# Generic_ARMv6M register map
Vendor: ARM Ltd.; Series: ARMv6-M architecture (Cortex-M0 / Cortex-M0+ / Cortex-M1 / SC000); File version: 1.0
CPU: CM0 r0p0, little endian, no MPU, no FPU, 2 interrupt priority bits
Registers are 32-bit, read-write, reset 0x0 unless marked. A register's access mark holds for its fields unless they carry their own. Offsets are from the block's base; [hi:lo] are bit positions; {n}, {i} and the like mark numbered series.

## NVIC — Nested Vectored Interrupt Controller. ARMv6-M caps external interrupts at 32 (5-bit encoding), so exactly one ISER/ICER/ISPR/ICPR register and 8 IPR registers cover the whole architectural range -- true for every ARMv6-M device regardless of how many interrupt lines it actually implements (unimplemented lines simply read as 0 / writes ignored). No IABR and no STIR on ARMv6-M (both are ARMv7-M+ only).
Base 0xE000E100
0x00 ISER — Interrupt Set-Enable Register
  [31:0] SETENA
0x80 ICER — Interrupt Clear-Enable Register
  [31:0] CLRENA
0x100 ISPR — Interrupt Set-Pending Register
  [31:0] SETPEND
0x180 ICPR — Interrupt Clear-Pending Register
  [31:0] CLRPEND
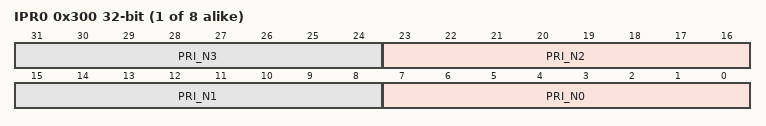
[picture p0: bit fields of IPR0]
{0x300+4i} IPR{i} (i=0..7) — Interrupt Priority Register {i} (covers IRQ{4i}..IRQ{4i+3})
  [8n+7:8n] PRI_N{n} (n=0..3) — Priority, byte offset {n}

## SCB — System Control Block, ARMv6-M register set. Verified against CMSIS_6 core_cm0.h/core_cm0plus.h defines. No SHPR1, no CFSR/HFSR/MMFAR/BFAR/AFSR (no MemManage/BusFault/UsageFault on v6-M), no AIRCR.PRIGROUP/VECTRESET, no ICSR.RETTOBASE (all ARMv7-M+ only). SHCSR exists but with only one bit (SVCALLPENDED) implemented. VTOR is present in the address map but is only wired up on implementations with __VTOR_PRESENT=1 (e.g. Cortex-M0+); on plain Cortex-M0 that offset is reserved. SHCSR and DFSR are only accessible over the DAP (debugger), not from application code -- see the CoreDebug peripheral's description.
Base 0xE000ED00
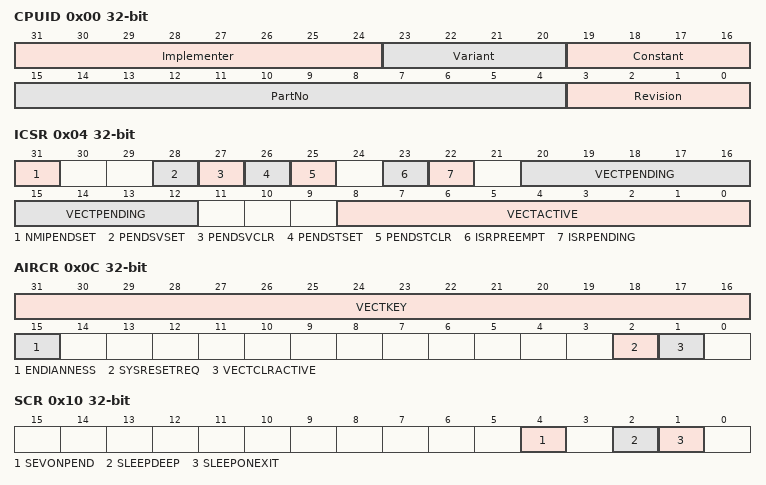
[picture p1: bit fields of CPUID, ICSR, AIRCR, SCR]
0x00 CPUID ro — CPUID Base Register. Reset value is implementation/revision specific.
  [31:24] Implementer — 0x41 = 'A' = ARM
  [23:20] Variant — Implementation specific variant number
  [19:16] Constant — Reads as 0xC for ARMv6-M, 0xF for ARMv7-M/ARMv8-M
  [15:4] PartNo — Implementation specific part number
  [3:0] Revision — Implementation/revision specific (e.g. r0p0 = 0x0)
0x04 ICSR — Interrupt Control and State Register. No RETTOBASE (ARMv7-M+ only).
  [31] NMIPENDSET
  [28] PENDSVSET
  [27] PENDSVCLR wo
  [26] PENDSTSET
  [25] PENDSTCLR wo
  [23] ISRPREEMPT ro — Only meaningful with a debugger attached
  [22] ISRPENDING ro
  [20:12] VECTPENDING — Pending exception number
  [8:0] VECTACTIVE — Active exception number
0x08 VTOR — Vector Table Offset Register -- OPTIONAL: only present if the implementation sets __VTOR_PRESENT=1 (common on Cortex-M0+, absent on plain Cortex-M0). Reads as 0 / reserved otherwise.
  [31:7] TBLOFF — Vector table base offset, 128-byte aligned
0x0C AIRCR — Application Interrupt and Reset Control Register. No PRIGROUP or VECTRESET (both ARMv7-M+ only -- v6-M has no configurable priority grouping).
  [31:16] VECTKEY — Write 0x05FA to permit the write; reads as 0xFA05
  [15] ENDIANNESS ro — Renamed from ENDIANESS in CMSIS_6 (kept as a deprecated alias there)
  [2] SYSRESETREQ
  [1] VECTCLRACTIVE — Reserved for debug use
0x10 SCR — System Control Register
  [4] SEVONPEND, [2] SLEEPDEEP, [1] SLEEPONEXIT
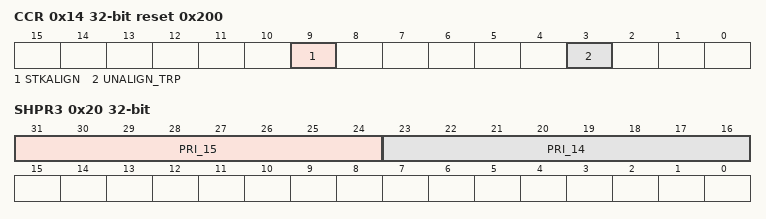
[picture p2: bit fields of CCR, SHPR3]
0x14 CCR reset 0x200 — Configuration and Control Register
  [9] STKALIGN — Always reads as 1: 8-byte stack alignment on exception entry
  [3] UNALIGN_TRP — Trap on unaligned word/halfword access
0x1C SHPR2 — System Handler Priority Register 2
  [31:24] PRI_11 — Priority of exception 11, SVCall
0x20 SHPR3 — System Handler Priority Register 3
  [31:24] PRI_15 — Priority of exception 15, SysTick
  [23:16] PRI_14 — Priority of exception 14, PendSV
0x24 SHCSR — System Handler Control and State Register. DAP-only access on ARMv6-M.
  [15] SVCALLPENDED — The only bit implemented on ARMv6-M

## MPU — Memory Protection Unit -- OPTIONAL on ARMv6-M: never present on plain Cortex-M0, but commonly implemented on Cortex-M0+ and SC000 (__MPU_PRESENT=1). No alias registers on this profile (verified against CMSIS core_cm0plus.h: MPU_TYPE_RALIASES=1, i.e. RBAR/RASR only).
Base 0xE000ED90
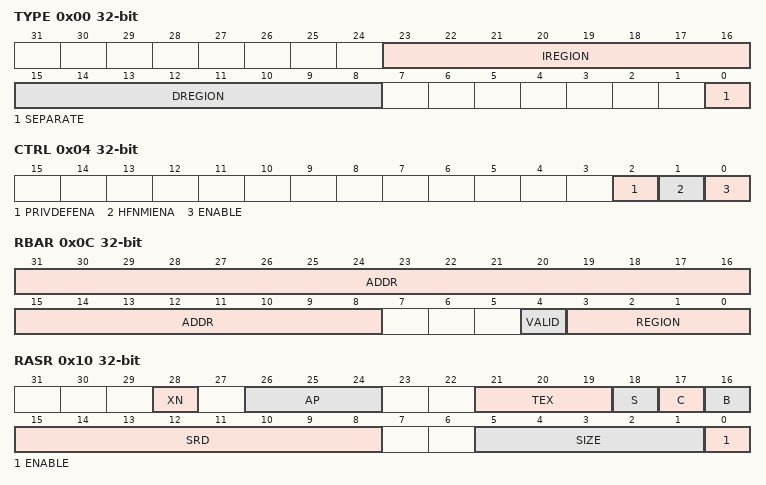
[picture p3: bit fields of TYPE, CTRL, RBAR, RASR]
0x00 TYPE ro — MPU Type Register
  [23:16] IREGION, [15:8] DREGION, [0] SEPARATE
0x04 CTRL — MPU Control Register
  [2] PRIVDEFENA, [1] HFNMIENA, [0] ENABLE
0x08 RNR — MPU Region Number Register
  [7:0] REGION
0x0C RBAR — MPU Region Base Address Register
  [31:8] ADDR, [4] VALID, [3:0] REGION
0x10 RASR — MPU Region Attribute and Size Register
  [28] XN, [26:24] AP, [21:19] TEX, [18] S, [17] C, [16] B, [15:8] SRD, [5:1] SIZE, [0] ENABLE

## SysTick — SysTick Timer. Identical register set on every Cortex-M core (ARMv6-M through current ARMv8-M).
Base 0xE000E010
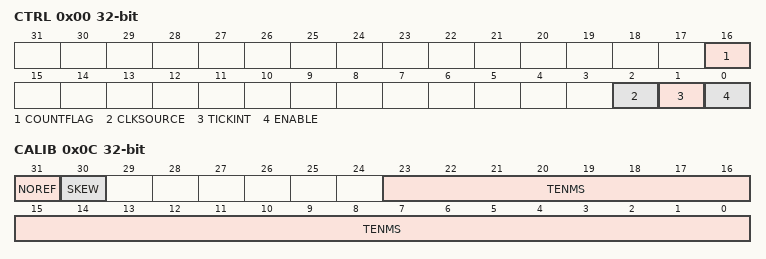
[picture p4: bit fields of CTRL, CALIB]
0x00 CTRL — SysTick Control and Status Register
  [16] COUNTFLAG ro, [2] CLKSOURCE, [1] TICKINT, [0] ENABLE
0x04 LOAD — SysTick Reload Value Register
  [23:0] RELOAD
0x08 VAL — SysTick Current Value Register. Any write clears it to 0 and clears COUNTFLAG.
  [23:0] CURRENT
0x0C CALIB ro — SysTick Calibration Value Register
  [31] NOREF, [30] SKEW, [23:0] TENMS

## DCB — Debug Control Block (DHCSR, DCRSR, DCRDR, DEMCR) -- named "CoreDebug" prior to CMSIS_6, which renamed it to DCB across the whole M-profile line ("CoreDebug"/"CoreDebug_Type" remain as deprecated aliases for the same registers). Fixed ADIv5/CoreSight debug architecture -- identical on every Cortex-M core. On ARMv6-M these registers are only accessible over the external Debug Access Port (DAP) by a debugger/probe -- application/firmware code running on the processor cannot read or write them via normal load/store instructions (confirmed in CMSIS core_cm0.h/core_cm0plus.h: "Core Debug Registers ... are only accessible over DAP and not via processor"). On ARMv7-M and later they ARE accessible from firmware. Cortex-M0/M0+'s own headers still don't define this struct at all (DAP-only, "not covered by the header file") -- the register content here is cross-referenced from core_cm4.h/core_cm7.h for documentation purposes.
Base 0xE000EDF0
0x00 DHCSR — Debug Halting Control and Status Register
  [25] S_RESET_ST ro
  [24] S_RETIRE_ST ro
  [19] S_LOCKUP ro
  [18] S_SLEEP ro
  [17] S_HALT ro
  [16] S_REGRDY ro
  [31:16] DBGKEY wo — Write 0xA05F to enable write access to bits [15:0]; reads as 0
  [5] C_SNAPSTALL
  [3] C_MASKINTS
  [2] C_STEP
  [1] C_HALT
  [0] C_DEBUGEN
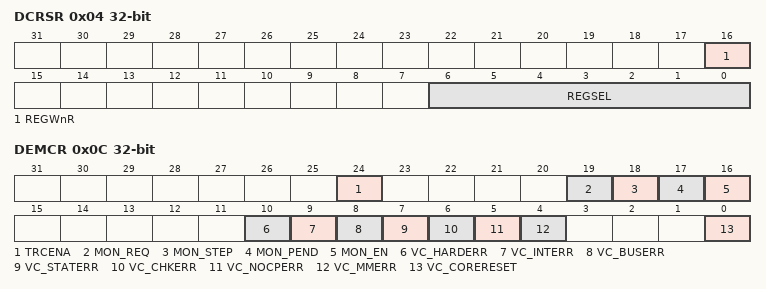
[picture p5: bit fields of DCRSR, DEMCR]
0x04 DCRSR wo — Debug Core Register Selector Register
  [16] REGWnR
  [6:0] REGSEL — Widened from 5 to 7 bits in CMSIS_6
0x08 DCRDR — Debug Core Register Data Register
  [31:0] DBGTMP
0x0C DEMCR — Debug Exception and Monitor Control Register. On ARMv6-M only VC_CORERESET and TRCENA are architecturally defined; the fault-related VC_* bits and the monitor MON_* bits apply from ARMv7-M up (v6-M has no MemManage/BusFault/UsageFault/Debug-Monitor exception, so those control bits do not exist there -- included here for completeness/documentation, treat as reserved on v6-M).
  [24] TRCENA — Trace enable (DWT/ITM/ETM/TPIU) -- only meaningful where those blocks exist
  [19] MON_REQ — Debug Monitor request -- ARMv7-M and later only
  [18] MON_STEP — Debug Monitor step -- ARMv7-M and later only
  [17] MON_PEND — Debug Monitor pend -- ARMv7-M and later only
  [16] MON_EN — Debug Monitor enable -- ARMv7-M and later only
  [10] VC_HARDERR — Debug trap on HardFault exception
  [9] VC_INTERR — Debug trap on interrupt/exception service errors -- ARMv7-M and later only
  [8] VC_BUSERR — Debug trap on BusFault exception -- ARMv7-M and later only
  [7] VC_STATERR — Debug trap on UsageFault state error -- ARMv7-M and later only
  [6] VC_CHKERR — Debug trap on UsageFault caused by checking error -- ARMv7-M and later only
  [5] VC_NOCPERR — Debug trap on UsageFault caused by no coprocessor -- ARMv7-M and later only
  [4] VC_MMERR — Debug trap on MemManage exception -- ARMv7-M and later only
  [0] VC_CORERESET — Reset Vector Catch
